# max32660 register map
Vendor: Maxim Integrated; Series: ARMCM4; File version: 1.0
MAX32660 32-bit ARM Cortex-M4 microcontroller with 96KB of system RAM and 256KB of flash memory.
CPU: CM4 r2p1, little endian, MPU, FPU, 3 interrupt priority bits
Registers are 32-bit, read-write, reset 0x0 unless marked. A register's access mark holds for its fields unless they carry their own. Offsets are from the block's base; lines under a group give offsets from that group; [hi:lo] are bit positions; {n}, {i} and the like mark numbered series; 'fields as' and 'values as' point back to an identical list; <NAME> marks a mode.

## Memory map
0x40000000 GCR size 0x400 — Global Control Registers.
0x40000400 SIR size 0x400 — System Initialization Registers.
0x40003000 WDT0 size 0x400 — Watchdog Timer 0
0x40004000 SMON size 0x1000 — The Security Monitor block used to monitor system threat conditions.
0x40005400 BBSIR size 0x400 — Battery-Backed Registers.
0x40005800 BBFC size 0x400 — Battery-Backed Function Control.
0x40006000 RTC size 0x400 — Real Time Clock and Alarm.
0x40006800 PWRSEQ size 0x800 — Power Sequencer / Low Power Control Register.
0x40008000 GPIO0 size 0x1000 — Individual I/O for each GPIO
0x40010000 TMR0 size 0x1000 — 32-bit reloadable timer that can be used for timing and event counting.
0x40011000 TMR1 size 0x1000 — 32-bit reloadable timer that can be used for timing and event counting. 1
0x40012000 TMR2 size 0x1000 — 32-bit reloadable timer that can be used for timing and event counting. 2
0x40019000 SPIMSS size 0x1000 — Serial Peripheral Interface.
0x4001D000 I2C0 size 0x1000 — Inter-Integrated Circuit.
0x4001E000 I2C1 size 0x1000 — Inter-Integrated Circuit. 1
0x40028000 DMA size 0x1000 — DMA Controller Fully programmable, chaining capable DMA channels.
0x40029000 FLC size 0x1000 — Flash Memory Control.
0x4002A000 ICC0 size 0x1000 — Instruction Cache Controller Registers
0x4002F000 ICC1 size 0x1000 — Instruction Cache Controller Registers 1
0x40042000 UART0 size 0x1000 — UART
0x40043000 UART1 size 0x1000
0x40046000 SPI17Y size 0x1000 — SPI peripheral.

## Interrupts
1 WDT0
3 RTC — RTC interrupt.
5 TMR0 — TMR0 IRQ
6 TMR1 — TMR1 IRQ
7 TMR2 — TMR2 IRQ
13 I2C0 — I2C0 IRQ
14 UART0 — UART0 IRQ
15 UART1 — UART1 IRQ
16 SPI0 (SPI17Y)
23 Flash_Controller (FLC) — Flash Controller interrupt.
24 GPIO0 — GPIO0 interrupt.
28 DMA0 (DMA)
29 DMA1 (DMA)
30 DMA2 (DMA)
31 DMA3 (DMA)
36 I2C1 — I2C1 IRQ

## BBFC — Battery-Backed Function Control.
Base 0x40005800
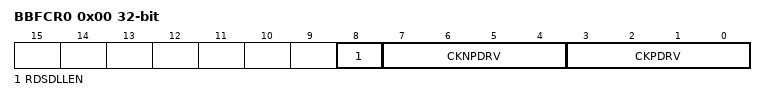
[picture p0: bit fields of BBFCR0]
0x00 BBFCR0 — Function Control Register 0.
  [8] RDSDLLEN — Hyperbus RDS DLL Power Up Control.
    0=dis (Disabled.); 1=en (Enabled.)
  [7:4] CKNPDRV — Hyperbus CKN Pad Driver Control.
  [3:0] CKPDRV — Hyperbus CK Pad Driver Control.

## BBSIR — Battery-Backed Registers.
Base 0x40005400
0x00 rsv0 — RFU
0x08 BB_SIR2 ro — System Init. Configuration Register 2.
0x0C BB_SIR3 ro — System Init. Configuration Register 3.

## FLC — Flash Memory Control.
Base 0x40029000; register names take the prefix FLSH_
0x00 ADDR — Flash Write Address.
  [31:0] ADDR — Address for next operation.
0x04 CLKDIV reset 0x64 — Flash Clock Divide. The clock (PLL0) is divided by this value to generate a 1 MHz clock for Flash controller.
  [7:0] CLKDIV — Flash Clock Divide. The clock is divided by this value to generate a 1MHz clock for flash controller.
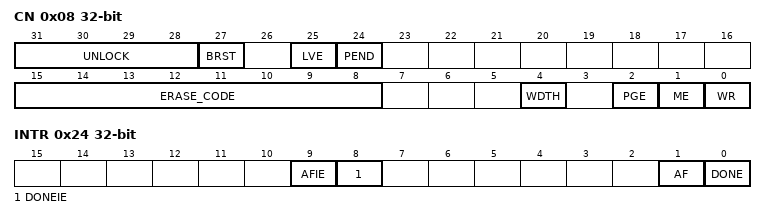
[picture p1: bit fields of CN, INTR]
0x08 CN — Flash Control Register.
  [31:28] UNLOCK — Flash Unlock. The correct unlock code must be written to these four bits before any Flash write or erase operation is allowed.
    2=unlocked (Flash Unlocked); 3=locked (Flash Locked)
  [27] BRST — Burst Mode Enable.
    0=disable; 1=enable
  [25] LVE ro — Low Voltage Read Enable
    on read: 0=dis (Disabled); 1=en (Enabled)
  [24] PEND ro — Flash Pending. When Flash operation is in progress (busy), Flash reads and writes will fail. When PEND is set, write to all Flash registers, with exception of the Flash interrupt register, are ignored.
    0=idle; 1=busy
  [15:8] ERASE_CODE — Erase Code. The ERASE_CODE must be set up property before erase operation can be initiated. These bits are automatically cleared after the operation is complete.
    0=nop (No operation.); 85=erasePage (Enable Page Erase.); 170=eraseAll (Enable Mass Erase. The debug port must be enabled.)
  [4] WDTH — Data Width. This bits selects write data width.
    0=size128 (128-bit.); 1=size32 (32-bit.)
  [2] PGE — Page Erase. This bit is automatically cleared after the operation.
    0=complete (No operation/complete.); 1=Start operation
  [1] ME — Mass Erase. This bit is automatically cleared after the operation.
    0=complete (No operation/complete.); 1=Start operation
  [0] WR — Write. This bit is automatically cleared after the operation.
    0=complete (No operation/complete.); 1=Start operation
0x24 INTR — Flash Interrupt Register.
  [9] AFIE — Flash Done Interrupt Enable.
    0=disable; 1=enable
  [8] DONEIE — Flash Done Interrupt Enable.
    0=disable; 1=enable
  [1] AF — Flash Access Fail. This bit is set when an attempt is made to write the flash while the flash is busy or the flash is locked. This bit can only be set to 1 by hardware.
    0=noError (No Failure.); 1=error (Failure occurs.)
  [0] DONE — Flash Done Interrupt. This bit is set to 1 upon Flash write or erase completion.
    0=inactive (No interrupt is pending); 1=pending (An interrupt is pending)
{0x30+4i} DATA[{i}] (i=0..3) — Flash Write Data.
  [31:0] DATA — Data next operation.
0x40 ACNTL wo — Access Control Register. Writing the ACNTL register with the following values in the order shown, allows read and write access to the system and user Information block: pflc-acntl = 0x3a7f5ca3; pflc-acntl = 0xa1e34f20; pflc-acntl = 0x9608b2c1. When unlocked, a write of any word will disable access to system and user information block. Readback of this register is always zero.
  [31:0] ACNTL — Access control.
